# R40 register map
Vendor: Allwinner; Series: R40; File version: 0.1
CPU: CA7 0, little endian, MPU, FPU, double-precision FPU, 0 interrupt priority bits
Registers are 32-bit, read-write, reset 0x0 unless marked. A register's access mark holds for its fields unless they carry their own. Offsets are from the block's base; [hi:lo] are bit positions; {n}, {i} and the like mark numbered series.

## RTC
Base 0x01C20400
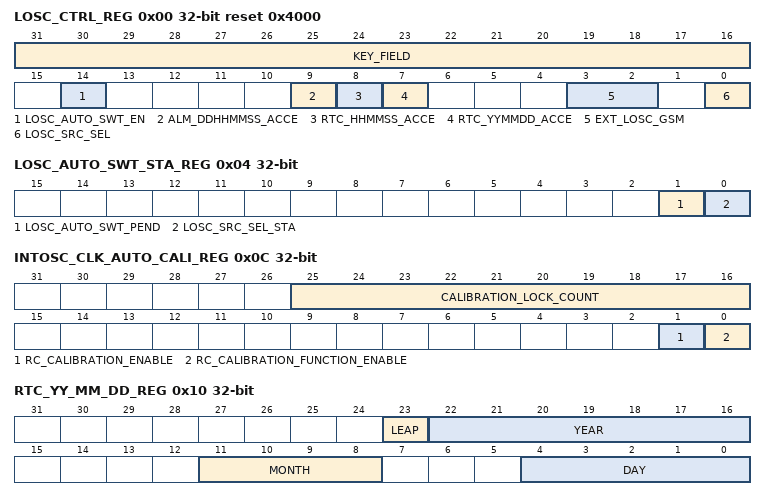
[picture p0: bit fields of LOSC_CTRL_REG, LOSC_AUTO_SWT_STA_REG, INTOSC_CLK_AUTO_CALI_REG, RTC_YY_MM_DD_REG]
0x00 LOSC_CTRL_REG reset 0x4000 — Low Oscillator Control Register
  [31:16] KEY_FIELD wo — Key Field. This field should be filled with 0x16AA, and then the bit 0 can be written with the new value.
  [14] LOSC_AUTO_SWT_EN — LOSC auto switch enable. 0: Disable 1: Enable.
    0=Disable; 1=Enable
  [9] ALM_DDHHMMSS_ACCE — ALARM DD-HH-MM-SS access. After wrote the , this bit is set and it will be cleared until the real writing operation is finished.
  [8] RTC_HHMMSS_ACCE — RTC HH-MM-SS access. After wrote the , this bit is set and it will be cleared until the real writing operation is finished. After wrote the , the will be refreshed for at most one second.
  [7] RTC_YYMMDD_ACCE — RTC YY-MM-DD access. After wrote the , this bit is set and it will be cleared until the real writing operation is finished. After wrote the , the will be refreshed for at most one second.
  [3:2] EXT_LOSC_GSM — External 32768Hz Crystal GSM. 00: Low 01: / 10: / 11 High
    0=Low; 2=_slash_ (/ 11 High)
  [0] LOSC_SRC_SEL — LOSC Clock source Select. `N` is the value of Internal OSC Clock Prescalar register. 0: 32KHz 1: External 32.768KHz OSC.
    0=_32KHz; 1=External 32.768KHz OSC
0x04 LOSC_AUTO_SWT_STA_REG — LOSC Auto Switch Status Register
  [1] LOSC_AUTO_SWT_PEND write-1-clears — LOSC auto switch pending. 0: No effect 1: Auto switches pending Writing 1 to this bit will clear it.
    0=No_effect; 1=Auto switches pending Writing 1 to this bit will clear it
  [0] LOSC_SRC_SEL_STA ro — Checking LOSC Clock Source Status. `N` is the value of Internal OSC Clock Prescalar register. 0: 32KHz 1: External 32.768KHz OSC
    0=_32KHz; 1=External 32.768KHz OSC
0x08 INTOSC_CLK_PRESCAL_REG reset 0xF — Internal OSC Clock Prescalar Register
  [4:0] INTOSC_CLK_PRESCAL — Internal OSC Clock Prescalar value N. 00000: 1 00001: 2 00010: 3 ...... 11111: 512
    0=_1; 1=_2; 2=_3; 31=_512
0x0C INTOSC_CLK_AUTO_CALI_REG — Internal OSC Clock Auto Calibration Register
  [25:16] CALIBRATION_LOCK_COUNT ro — 32k calibration lock count.
  [1] RC_CALIBRATION_ENABLE
  [0] RC_CALIBRATION_FUNCTION_ENABLE
0x10 RTC_YY_MM_DD_REG — RTC Year-Month-Day Register
  [23] LEAP — Leap Year. 0: Not 1: Leap year. This bit can not set by hardware. It should be set or cleared by software.
    0=Not; 1=Leap year. This bit can not set by hardware. It should be set or cleared by software.
  [22:16] YEAR — Year. Range from 0~127.
  [11:8] MONTH — Month. Range from 1~12.
  [4:0] DAY — Day. Range from 1~31.
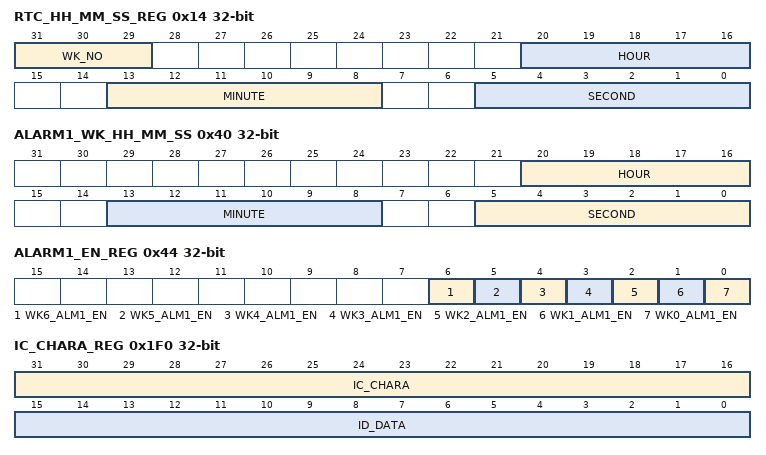
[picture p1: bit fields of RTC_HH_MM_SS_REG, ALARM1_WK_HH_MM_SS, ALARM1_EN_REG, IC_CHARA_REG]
0x14 RTC_HH_MM_SS_REG — RTC Hour-Minute-Second Register
  [31:29] WK_NO — Week number. 000: Monday 001: Tuesday 010: Wednesday 011: Thursday 100: Friday 101: Saturday 110: Sunday 111: /
    0=Monday; 1=Tuesday; 2=Wednesday; 3=Thursday; 4=Friday; 5=Saturday; 6=Sunday
  [20:16] HOUR — Range from 0~23
  [13:8] MINUTE — Range from 0~59
  [5:0] SECOND — Range from 0~59
0x20 ALARM0_COUNTER_REG — Alarm 0 Counter Register
  [31:0] ALARM0_COUNTER — Alarm 0 Counter is Based on Second.
0x24 ALARM0_CUR_VAL_REG
  [31:0] ALARM0_CUR_VLU ro — Check Alarm 0 Counter Current Values.
0x28 ALARM0_ENABLE_REG — Alarm 0 Enable Register
  [0] ALM_0_EN — Alarm 0 Enable. If this bit is set to `1`, the valid bits of will down count to zero, and the alarm pending bit will be set to `1`. 0: Disable 1: Enable
    0=Disable; 1=Enable
0x2C ALARM0_IRQ_EN_REG
  [0] ALARM0_IRQ_EN — Alarm 0 IRQ Enable. 0: Disable 1: Enable
    0=Disable; 1=Enable
0x30 ALARM0_IRQ_STA_REG — Alarm 0 IRQ Status Register
  [0] ALARM0_IRQ_PEND write-1-clears — Alarm 0 IRQ Pending bit. 0: No effect 1: Pending, alarm 0 counter value is reached If alarm 0 irq enable is set to 1, the pending bit will be sent to the interrupt controller.
    0=No_effect; 1=Pending, alarm 0 counter value is reached If alarm 0 irq enable is set to 1, the pending bit will be sent to the interrupt controller
0x40 ALARM1_WK_HH_MM_SS
  [20:16] HOUR — Range from 0~23.
  [13:8] MINUTE — Range from 0~59.
  [5:0] SECOND — Range from 0~59.
0x44 ALARM1_EN_REG
  [6] WK6_ALM1_EN — Week 6 (Sunday) Alarm 1 Enable. 0: Disable 1: Enable If this bit is set to `1`, only when the valid bits of is equal to the bit[20:0] of and the bit[31:29] of is 6, the week 6 alarm irq pending bit will be set to `1`.
    0=Disable; 1=Enable If this bit is set to `1`, only when the valid bits of is equal to the bit[20:0] of and the bit[31:29] of is 6, the week 6 alarm irq pending bit will be set to `1`
  [5] WK5_ALM1_EN — Week 5 (Saturday) Alarm 1 Enable. 0: Disable 1: Enable If this bit is set to `1`, only when the valid bits of is equal to the bit[20:0] of and the bit[31:29] of is 5, the week 5 alarm irq pending bit will be set to `1`.
    0=Disable; 1=Enable If this bit is set to `1`, only when the valid bits of is equal to the bit[20:0] of and the bit[31:29] of is 5, the week 5 alarm irq pending bit will be set to `1`
  [4] WK4_ALM1_EN — Week 4 (Friday) Alarm 1 Enable. 0: Disable 1: Enable If this bit is set to `1`, only when the valid bits of is equal to the bit[20:0] of and the bit[31:29] of is 4, the week 4 alarm irq pending bit will be set to `1`.
    0=Disable; 1=Enable If this bit is set to `1`, only when the valid bits of is equal to the bit[20:0] of and the bit[31:29] of is 4, the week 4 alarm irq pending bit will be set to `1`
  [3] WK3_ALM1_EN — Week 3 (Thursday) Alarm 1 Enable. 0: Disable 1: Enable If this bit is set to `1`, only when the valid bits of is equal to the bit[20:0] of and the bit[31:29] of is 3, the week 3 alarm irq pending bit will be set to `1`.
    0=Disable; 1=Enable If this bit is set to `1`, only when the valid bits of is equal to the bit[20:0] of and the bit[31:29] of is 3, the week 3 alarm irq pending bit will be set to `1`
  [2] WK2_ALM1_EN — Week 2 (Wednesday) Alarm 1 Enable. 0: Disable 1: Enable If this bit is set to `1`, only when the valid bits of is equal to the bit[20:0] of and the bit[31:29] of is 2, the week 2 alarm irq pending bit will be set to `1`.
    0=Disable; 1=Enable If this bit is set to `1`, only when the valid bits of is equal to the bit[20:0] of and the bit[31:29] of is 2, the week 2 alarm irq pending bit will be set to `1`
  [1] WK1_ALM1_EN — Week 1 (Tuesday) Alarm 1 Enable. 0: Disable 1: Enable If this bit is set to `1`, only when the valid bits of is equal to the bit[20:0] of and the bit[31:29] of is 1, the week 1 alarm irq pending bit will be set to `1`.
    0=Disable; 1=Enable If this bit is set to `1`, only when the valid bits of is equal to the bit[20:0] of and the bit[31:29] of is 1, the week 1 alarm irq pending bit will be set to `1`
  [0] WK0_ALM1_EN — Week 0 (Monday) Alarm 1 Enable. 0: Disable 1: Enable If this bit is set to `1`, only when the valid bits of is equal to the bit[20:0] of and the bit[31:29] of is 0, the week 0 alarm irq pending bit will be set to `1`.
    0=Disable; 1=Enable If this bit is set to `1`, only when the valid bits of is equal to the bit[20:0] of and the bit[31:29] of is 0, the week 0 alarm irq pending bit will be set to `1`
0x48 ALARM1_IRQ_EN_REG
  [0] ALARM1_IRQ_EN — Alarm 1 IRQ Enable. 0: Disable 1: Enable
    0=Disable; 1=Enable
0x4C ALARM1_IRQ_STA_REG — Alarm 1 IRQ Status Register
  [0] ALARM1_WEEK_IRQ_PEND write-1-clears — Alarm 1 Week (0/1/2/3/4/5/6) IRQ Pending. 0: No effect 1: Pending, week counter value is reached If alarm 1 week irq enable is set to 1, the pending bit will be sent to the interrupt controller.
    0=No_effect; 1=Pending, week counter value is reached If alarm 1 week irq enable is set to 1, the pending bit will be sent to the interrupt controller
0x50 ALARM_CONFIG_REG — Alarm Configuration Register
  [0] ALARM_WAKEUP — Configuration of alarm wake up output. 0: Disable alarm wake up output 1: Enable alarm wake up output
    0=Disable alarm wake up output; 1=Enable alarm wake up output
{0x100+4i} GP_DATA_REGn[{i}] (i=0..7) — GP_DATA_REGn[{i}]
  [31:0] GP_DATA — Data [31:0].
0x190 VDD_RTC_REG reset 0x4 — VDD RTC Regulate Register
  [2:0] VDD_RTC_REGU — These bits are useful for regulating the RTC_VIO from 0.7V to 1.4V, and the regulation step is 0.1V. 000: 0.7V 001: 0.8V 010: 0.9V 011: 1.0V 100: 1.1V 101: 1.2V 110: 1.3V 111: 1.4V
    0=_0_point_7V (0.7V); 1=_0_point_8V (0.8V); 2=_0_point_9V (0.9V); 3=_1_point_0V (1.0V); 4=_1_point_1V (1.1V); 5=_1_point_2V (1.2V); 6=_1_point_3V (1.3V); 7=_1_point_4V (1.4V)
0x1F0 IC_CHARA_REG — IC Characteristic Register
  [31:16] IC_CHARA — Key Field. The field should be written to 0x16AA. Writing any other value in this field aborts the write operation.
  [15:0] ID_DATA — Return 0x16AA only if the is set as 0x16AA when read those bits, otherwise return 0x0.
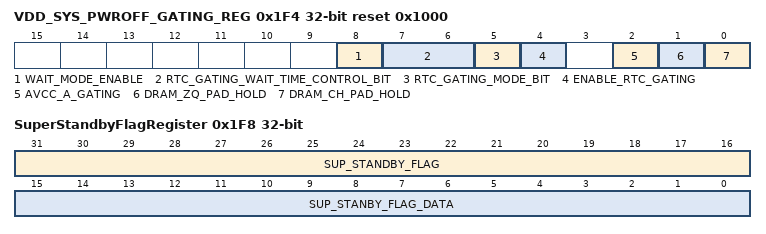
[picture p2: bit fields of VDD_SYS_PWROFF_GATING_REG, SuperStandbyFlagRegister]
0x1F4 VDD_SYS_PWROFF_GATING_REG reset 0x1000 — VDD_SYS Power Off Gating Register
  [8] WAIT_MODE_ENABLE
  [7:6] RTC_GATING_WAIT_TIME_CONTROL_BIT
  [5] RTC_GATING_MODE_BIT — 0: Wait mode 1: VDD Off clear mode
    0=Wait_mode; 1=VDD (VDD Off clear mode)
  [4] ENABLE_RTC_GATING
  [2] AVCC_A_GATING — Gating the corresponding modules to the AVCC_A Power Domain when VDD_SYS power off. 0: Invalid 1: Valid Note: This bit should be set to 1 before VDD_SYS power off while it should be set to 0 after the VDD_SYS power on.
    0=Invalid; 1=Valid Note: This bit should be set to 1 before VDD_SYS power off while it should be set to 0 after the VDD_SYS power on
  [1] DRAM_ZQ_PAD_HOLD — Hold the pad of DRAM channel 0: Not hold 1: Hold DRAM ZQ Pad Note: This bit should be set to 1 before VDD_SYS power off while it should be set to 0 after the VDD_SYS power on.
    0=Not_hold; 1=Hold DRAM ZQ Pad Note: This bit should be set to 1 before VDD_SYS power off while it should be set to 0 after the VDD_SYS power on
  [0] DRAM_CH_PAD_HOLD — Hold the pad of DRAM channel 0: Not hold 1: Hold DRAM Pad Note: This bit should be set to 1 before VDD_SYS power off while it should be set to 0 after the VDD_SYS power on.
    0=Not_hold; 1=Hold DRAM Pad Note: This bit should be set to 1 before VDD_SYS power off while it should be set to 0 after the VDD_SYS power on
0x1F8 SuperStandbyFlagRegister
  [31:16] SUP_STANDBY_FLAG — Key Field. Any value can be written and read back in the key field, but if the values are not appropriate, the lower 16 bits will not change in this register. Only fellow the appropriate process, the super standby flag can be written in the lower 16 bits. Refer to Description and Diagram.
  [15:0] SUP_STANBY_FLAG_DATA — Refer to Description and Diagram
0x1FC CPU_SOFT_ENT_REG — CPU Software Entry Register
  [31:0] CPU_SOFT_ENT — CPU software entry register when acting from super standby.
